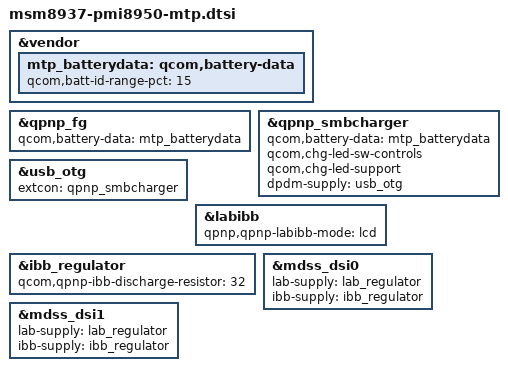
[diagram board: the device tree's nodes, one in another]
/*
 * Copyright (c) 2015-2016, 2018, The Linux Foundation. All rights reserved.
 *
 * This program is free software; you can redistribute it and/or modify
 * it under the terms of the GNU General Public License version 2 and
 * only version 2 as published by the Free Software Foundation.
 *
 * This program is distributed in the hope that it will be useful,
 * but WITHOUT ANY WARRANTY; without even the implied warranty of
 * MERCHANTABILITY or FITNESS FOR A PARTICULAR PURPOSE.  See the
 * GNU General Public License for more details.
 */

#include "pmi8950.dtsi"
#include "msm8937-mtp.dtsi"

&vendor {
	mtp_batterydata: qcom,battery-data {
		qcom,batt-id-range-pct = <15>;
		#include "batterydata-itech-3000mah.dtsi"
		#include "batterydata-ascent-3450mAh.dtsi"
	};
};

&qpnp_fg {
	qcom,battery-data = <&mtp_batterydata>;
};

&qpnp_smbcharger {
	qcom,battery-data = <&mtp_batterydata>;
	qcom,chg-led-sw-controls;
	qcom,chg-led-support;
	dpdm-supply = <&usb_otg>;
};

&usb_otg {
	extcon = <&qpnp_smbcharger>;
};

&labibb {
	status = "ok";
	qpnp,qpnp-labibb-mode = "lcd";
};

&ibb_regulator {
	qcom,qpnp-ibb-discharge-resistor = <32>;
};

&mdss_dsi0 {
	lab-supply = <&lab_regulator>;
	ibb-supply = <&ibb_regulator>;
};

&mdss_dsi1 {
	lab-supply = <&lab_regulator>;
	ibb-supply = <&ibb_regulator>;
};
